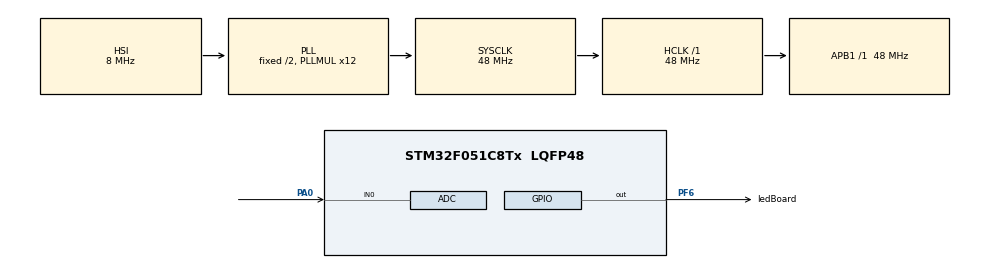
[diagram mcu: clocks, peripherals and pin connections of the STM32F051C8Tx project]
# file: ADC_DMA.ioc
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ADC.ContinuousConvMode=ENABLE
ADC.DMAContinuousRequests=ENABLE
ADC.SamplingTime=ADC_SAMPLETIME_239CYCLES_5
Dma.ADC.0.Direction=DMA_PERIPH_TO_MEMORY
Dma.ADC.0.Instance=DMA1_Channel1
Dma.ADC.0.MemDataAlignment=DMA_MDATAALIGN_WORD
Dma.ADC.0.MemInc=DMA_MINC_ENABLE
Dma.ADC.0.Mode=DMA_CIRCULAR
Dma.ADC.0.PeriphDataAlignment=DMA_PDATAALIGN_WORD
Dma.ADC.0.PeriphInc=DMA_PINC_DISABLE
Dma.ADC.0.Priority=DMA_PRIORITY_LOW
Dma.Request0=ADC
Mcu.Family=STM32F0
Mcu.Name=STM32F051C8Tx
Mcu.Package=LQFP48
NVIC.DMA1_Channel1_IRQn=true\:0\:0\:false\:false\:true\:false\:true\:true
PA0.Mode=IN0
PA0.Signal=ADC_IN0
PA13.Mode=Serial_Wire
PA13.Signal=SYS_SWDIO
PA14.Mode=Serial_Wire
PA14.Signal=SYS_SWCLK
PF6.GPIO_Label=ledBoard
PF6.Signal=GPIO_Output
ProjectManager.HeapSize=0x200
ProjectManager.StackSize=0x400
ProjectManager.TargetToolchain=STM32CubeIDE
RCC.AHBFreq_Value=48000000
RCC.APB1Freq_Value=48000000
RCC.APB1TimFreq_Value=48000000
RCC.HCLKFreq_Value=48000000
RCC.PLLMUL=RCC_PLL_MUL12
RCC.SYSCLKFreq_VALUE=48000000
RCC.SYSCLKSource=RCC_SYSCLKSOURCE_PLLCLK
board=custom

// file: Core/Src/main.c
/* USER CODE BEGIN Header */
/**
  ******************************************************************************
  * @file           : main.c
  * @brief          : Main program body
  ******************************************************************************
  * @attention
  *
  * Copyright (c) 2023 STMicroelectronics.
  * All rights reserved.
  *
  * This software is licensed under terms that can be found in the LICENSE file
  * in the root directory of this software component.
  * If no LICENSE file comes with this software, it is provided AS-IS.
  *
  ******************************************************************************
  */
/* USER CODE END Header */
#include "main.h"

ADC_HandleTypeDef hadc;
DMA_HandleTypeDef hdma_adc;

/* USER CODE BEGIN PV */
uint32_t ADC_DMA[1];

/* USER CODE END PV */

void SystemClock_Config(void);
static void MX_GPIO_Init(void);
static void MX_DMA_Init(void);
static void MX_ADC_Init(void);

int main(void)
{

  /* MCU Configuration--------------------------------------------------------*/

  /* Reset of all peripherals, Initializes the Flash interface and the Systick. */
  HAL_Init();

  /* Configure the system clock */
  SystemClock_Config();

  /* Initialize all configured peripherals */
  MX_GPIO_Init();
  MX_DMA_Init();
  MX_ADC_Init();
  /* USER CODE BEGIN 2 */
  HAL_ADC_Start_DMA(&hadc, ADC_DMA, 1);

  /* USER CODE END 2 */

  /* Infinite loop */
  /* USER CODE BEGIN WHILE */
  while (1)
  {
	  HAL_GPIO_TogglePin(ledBoard_GPIO_Port, ledBoard_Pin);
	  HAL_Delay(250);
    /* USER CODE END WHILE */

  }
}

void SystemClock_Config(void)
{
  RCC_OscInitTypeDef RCC_OscInitStruct = {0};
  RCC_ClkInitTypeDef RCC_ClkInitStruct = {0};

  /** Initializes the RCC Oscillators according to the specified parameters
  * in the RCC_OscInitTypeDef structure.
  */
  RCC_OscInitStruct.OscillatorType = RCC_OSCILLATORTYPE_HSI|RCC_OSCILLATORTYPE_HSI14;
  RCC_OscInitStruct.HSIState = RCC_HSI_ON;
  RCC_OscInitStruct.HSI14State = RCC_HSI14_ON;
  RCC_OscInitStruct.HSICalibrationValue = RCC_HSICALIBRATION_DEFAULT;
  RCC_OscInitStruct.HSI14CalibrationValue = 16;
  RCC_OscInitStruct.PLL.PLLState = RCC_PLL_ON;
  RCC_OscInitStruct.PLL.PLLSource = RCC_PLLSOURCE_HSI;
  RCC_OscInitStruct.PLL.PLLMUL = RCC_PLL_MUL12;
  RCC_OscInitStruct.PLL.PREDIV = RCC_PREDIV_DIV1;
  if (HAL_RCC_OscConfig(&RCC_OscInitStruct) != HAL_OK)
  {
    Error_Handler();
  }

  /** Initializes the CPU, AHB and APB buses clocks
  */
  RCC_ClkInitStruct.ClockType = RCC_CLOCKTYPE_HCLK|RCC_CLOCKTYPE_SYSCLK
                              |RCC_CLOCKTYPE_PCLK1;
  RCC_ClkInitStruct.SYSCLKSource = RCC_SYSCLKSOURCE_PLLCLK;
  RCC_ClkInitStruct.AHBCLKDivider = RCC_SYSCLK_DIV1;
  RCC_ClkInitStruct.APB1CLKDivider = RCC_HCLK_DIV1;

  if (HAL_RCC_ClockConfig(&RCC_ClkInitStruct, FLASH_LATENCY_1) != HAL_OK)
  {
    Error_Handler();
  }
}

static void MX_ADC_Init(void)
{

  ADC_ChannelConfTypeDef sConfig = {0};

  /** Configure the global features of the ADC (Clock, Resolution, Data Alignment and number of conversion)
  */
  hadc.Instance = ADC1;
  hadc.Init.ClockPrescaler = ADC_CLOCK_ASYNC_DIV1;
  hadc.Init.Resolution = ADC_RESOLUTION_12B;
  hadc.Init.DataAlign = ADC_DATAALIGN_RIGHT;
  hadc.Init.ScanConvMode = ADC_SCAN_DIRECTION_FORWARD;
  hadc.Init.EOCSelection = ADC_EOC_SINGLE_CONV;
  hadc.Init.LowPowerAutoWait = DISABLE;
  hadc.Init.LowPowerAutoPowerOff = DISABLE;
  hadc.Init.ContinuousConvMode = ENABLE;
  hadc.Init.DiscontinuousConvMode = DISABLE;
  hadc.Init.ExternalTrigConv = ADC_SOFTWARE_START;
  hadc.Init.ExternalTrigConvEdge = ADC_EXTERNALTRIGCONVEDGE_NONE;
  hadc.Init.DMAContinuousRequests = ENABLE;
  hadc.Init.Overrun = ADC_OVR_DATA_PRESERVED;
  if (HAL_ADC_Init(&hadc) != HAL_OK)
  {
    Error_Handler();
  }

  /** Configure for the selected ADC regular channel to be converted.
  */
  sConfig.Channel = ADC_CHANNEL_0;
  sConfig.Rank = ADC_RANK_CHANNEL_NUMBER;
  sConfig.SamplingTime = ADC_SAMPLETIME_239CYCLES_5;
  if (HAL_ADC_ConfigChannel(&hadc, &sConfig) != HAL_OK)
  {
    Error_Handler();
  }

}

static void MX_DMA_Init(void)
{

  /* DMA controller clock enable */
  __HAL_RCC_DMA1_CLK_ENABLE();

  /* DMA interrupt init */
  /* DMA1_Channel1_IRQn interrupt configuration */
  HAL_NVIC_SetPriority(DMA1_Channel1_IRQn, 0, 0);
  HAL_NVIC_EnableIRQ(DMA1_Channel1_IRQn);

}

static void MX_GPIO_Init(void)
{
  GPIO_InitTypeDef GPIO_InitStruct = {0};

  /* GPIO Ports Clock Enable */
  __HAL_RCC_GPIOA_CLK_ENABLE();
  __HAL_RCC_GPIOF_CLK_ENABLE();

  /*Configure GPIO pin Output Level */
  HAL_GPIO_WritePin(ledBoard_GPIO_Port, ledBoard_Pin, GPIO_PIN_RESET);

  /*Configure GPIO pin : ledBoard_Pin */
  GPIO_InitStruct.Pin = ledBoard_Pin;
  GPIO_InitStruct.Mode = GPIO_MODE_OUTPUT_PP;
  GPIO_InitStruct.Pull = GPIO_NOPULL;
  GPIO_InitStruct.Speed = GPIO_SPEED_FREQ_LOW;
  HAL_GPIO_Init(ledBoard_GPIO_Port, &GPIO_InitStruct);

}

void Error_Handler(void)
{
  __disable_irq();
  while (1)
  {
  }
}
